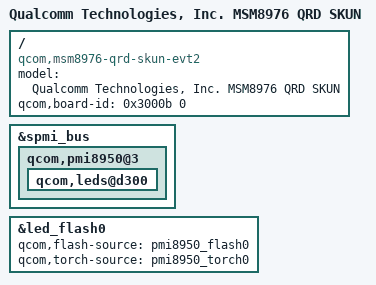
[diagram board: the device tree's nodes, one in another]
/*
 * Copyright (c) 2015, The Linux Foundation. All rights reserved.
 *
 * This program is free software; you can redistribute it and/or modify
 * it under the terms of the GNU General Public License version 2 and
 * only version 2 as published by the Free Software Foundation.
 *
 * This program is distributed in the hope that it will be useful,
 * but WITHOUT ANY WARRANTY; without even the implied warranty of
 * MERCHANTABILITY or FITNESS FOR A PARTICULAR PURPOSE.  See the
 * GNU General Public License for more details.
 */

/dts-v1/;

#include "msm8976-qrd-skun.dtsi"

/ {
	model = "Qualcomm Technologies, Inc. MSM8976 QRD SKUN";
	compatible = "qcom,msm8976-qrd-skun-evt2", "qcom,msm8976-qrd",
		   "qcom,msm8976", "qcom,qrd";
	qcom,board-id= <0x3000b 0>;
};

&spmi_bus {
	qcom,pmi8950@3 {
		qcom,leds@d300 {
			/delete-node/ qcom,flash_1;
			/delete-node/ qcom,torch_1;
		};
	};
};

&led_flash0{
	qcom,flash-source = <&pmi8950_flash0>;
	qcom,torch-source = <&pmi8950_torch0>;

};
